# AT32F413 register map
Vendor: Keil; Series: AT32F413; File version: 1.0
CPU: CM4 r0p1, little endian, no MPU, FPU, 4 interrupt priority bits
Registers are 32-bit, read-write, reset 0x0 unless marked. A register's access mark holds for its fields unless they carry their own. Offsets are from the block's base; [hi:lo] are bit positions; {n}, {i} and the like mark numbered series; 'fields as' and 'values as' point back to an identical list.

## WDT — Watchdog
Base 0x40003000
0x00 CMD — Command register
  [15:0] CMD
    0x5555=Unlock write-protected WDT_DIV and WDT_RLD; 0xAAAA=Reload counter; 0xCCCC=Enable WDT. If the hardware watchdog has been enabled, ignore this operation.
0x04 DIV — Division register
  [2:0] DIV — Division divider
    0=LICK divided by 4; 1=LICK divided by 8; 2=LICK divided by 16; 3=LICK divided by 32; 4=LICK divided by 64; 5=LICK divided by 128; 6=LICK divided by 256; 7=div256_2 (LICK divided by 256)
0x08 RLD reset 0xFFF — Reload register
  [11:0] RLD — Reload value
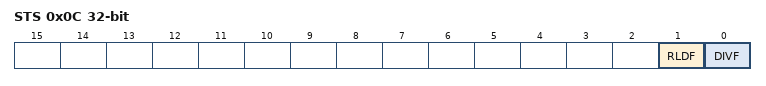
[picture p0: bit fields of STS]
0x0C STS ro — Status register
  [1] RLDF — Reload value update complete flag
    0=Complete (Reload value update complete); 1=InProgress (Reload value update is in process)
  [0] DIVF — Division value update complete flag
    0=Complete (Division value update complete); 1=InProgress (Division value update is in process)

## WWDT — Window watchdog
Base 0x40002C00
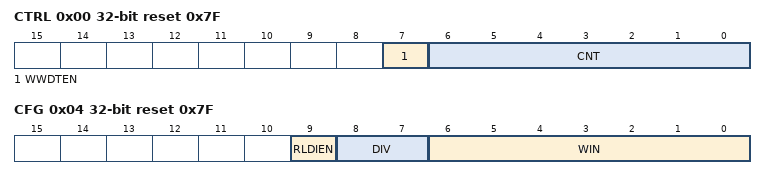
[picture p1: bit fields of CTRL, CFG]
0x00 CTRL reset 0x7F — Control register
  [7] WWDTEN write-1-sets — Window watchdog enable
    on read: 0=Disabled; 1=Enabled | on write: 1=Enable
  [6:0] CNT — Decrement counter
0x04 CFG reset 0x7F — Configuration register
  [9] RLDIEN — Reload counter interrupt
    on read: 0=Disabled; 1=Enabled | on write: 0=Disable; 1=Enable
  [8:7] DIV — Clock division value
    0=PCLK1 divided by 4096; 1=PCLK1 divided by 8192; 2=PCLK1 divided by 16384; 3=PCLK1 divided by 32768
  [6:0] WIN — Window value
0x08 STS — Status register
  [0] RLDF write-0-clears — Reload counter interrupt flag
    on read: 0=NotReached (Downcounter doesn't reached 0x40); 1=Reached (Downcounter reached 0x40) | on write: 0=Clear flag

## ACC — HICK Auto Clock Calibration
Base 0x40015800
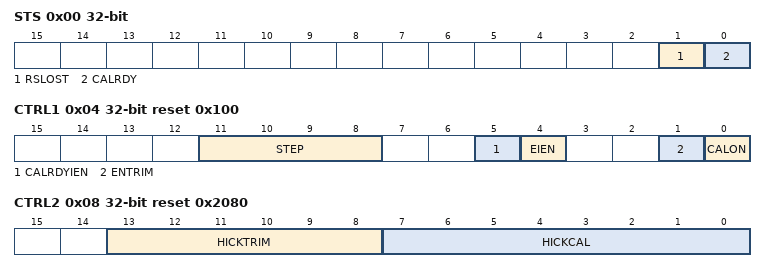
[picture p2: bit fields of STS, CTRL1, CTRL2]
0x00 STS ro — status register
  [1] RSLOST rw — Reference Signal Lost
    0=NotLost (Reference Signal is not lost); 1=Lost (Reference Signal is lost)
  [0] CALRDY rw — Internal high-speed clock calibration ready
    0=NotReady (Interal 8MHz oscillator calibration is not ready); 1=Ready (Interal 8MHz oscillator calibration is ready)
0x04 CTRL1 reset 0x100 — control register 1
  [11:8] STEP — Calibrated step
  [5] CALRDYIEN — CALRDY interrupt enable
    on read: 0=Disabled (Interrupt generation disabled); 1=Enabled (ACC interrupt is generated when CALRDY=1 in the ACC_STS register) | on write: 0=Disable (Interrupt generation disabled); 1=Enable (ACC interrupt is generated when CALRDY=1 in the ACC_STS register)
  [4] EIEN — RSLOST error interrupt enable
    on read: 0=Disabled (Interrupt generation disabled); 1=Enabled (ACC interrupt is generated when RSLOST=1 in the ACC_STS register) | on write: 0=Disable (Interrupt generation disabled); 1=Enable (ACC interrupt is generated when RSLOST=1 in the ACC_STS register)
  [1] ENTRIM — Enable trim
    0=HICKCAL (HICKCAL is calibrated); 1=HICKTRIM (HICKTRIM is calibrated)
  [0] CALON — Calibration on
    on read: 0=Disabled (Calibration disabled); 1=Enabled (Calibration enabled, and starts searching for a pulse on the USB_SOF) | on write: 0=Disable (Calibration disabled); 1=Enable (Calibration enabled, and starts searching for a pulse on the USB_SOF)
0x08 CTRL2 reset 0x2080 — control register 2
  [13:8] HICKTRIM ro — Internal high-speed auto clock trimming
  [7:0] HICKCAL ro — Internal high-speed auto clock calibration
0x0C C1 16-bit reset 0x1F2C — compare value 1
0x10 C2 16-bit reset 0x1F40 — compare value 2
0x14 C3 16-bit reset 0x1F54 — compare value 3

## DEBUG — Debug support
Base 0xE0042000
0x00 IDCODE ro — DEBUG_IDCODE
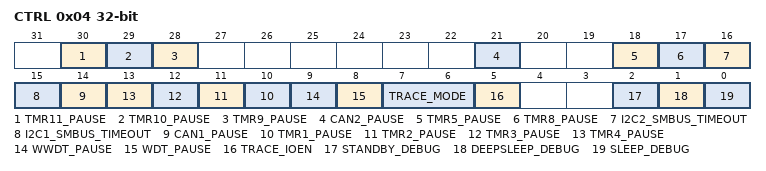
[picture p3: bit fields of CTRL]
0x04 CTRL — DEBUG_CTRL
  [30] TMR11_PAUSE — Timer pause control bit
    0=Continue (The counter clock of TMRx is fed even if the core is halted); 1=Pause (The counter clock of TMRx is stopped when the core is halted)
  [29] TMR10_PAUSE — Timer pause control bit
    values as TMR11_PAUSE
  [28] TMR9_PAUSE — Timer pause control bit
    values as TMR11_PAUSE
  [21] CAN2_PAUSE
  [18] TMR5_PAUSE — Timer pause control bit
    values as TMR11_PAUSE
  [17] TMR8_PAUSE — Timer pause control bit
    values as TMR11_PAUSE
  [16] I2C2_SMBUS_TIMEOUT
  [15] I2C1_SMBUS_TIMEOUT
  [14] CAN1_PAUSE
  [n+9] TMR{n}_PAUSE (n=1..4) — Timer pause control bit
    values as TMR11_PAUSE
  [9] WWDT_PAUSE
    values as TMR11_PAUSE
  [8] WDT_PAUSE
    values as TMR11_PAUSE
  [7:6] TRACE_MODE
  [5] TRACE_IOEN
  [2] STANDBY_DEBUG — Debug Standby mode control bit
    on read: 0=Disabled (The whole 1.2V digital circuit is unpowered in Standby mode); 1=Enabled (The whole 1.2V digital circuit is not unpowered in Standby mode, and the system clock is provided by the internal RC oscillator (HICK)) | on write: 0=Disable (The whole 1.2V digital circuit is unpowered in Standby mode); 1=Enable (The whole 1.2V digital circuit is not unpowered in Standby mode, and the system clock is provided by the internal RC oscillator (HICK))
  [1] DEEPSLEEP_DEBUG — Debug Deepsleep mode control bit
    on read: 0=Disabled (In Deepsleep mode, all clocks in the 1.2V domain are disabled); 1=Enabled (In Deepsleep mode, system clock is provided by the internal RC oscillator (HICK)) | on write: 0=Disable (In Deepsleep mode, all clocks in the 1.2V domain are disabled); 1=Enable (In Deepsleep mode, system clock is provided by the internal RC oscillator (HICK))
  [0] SLEEP_DEBUG — Debug Sleep mode control bit
    on read: 0=Disabled (When entering Sleep mode, CPU HCLK clock is disabled, but other clocks remain active); 1=Enabled (When entering Sleep mode, all clocks keep running) | on write: 0=Disable (When entering Sleep mode, CPU HCLK clock is disabled, but other clocks remain active); 1=Enable (When entering Sleep mode, all clocks keep running)
